# RX64M_POE_Pilot register map
File version: 1.0
RX64M_POE_Pilot peripheral registers generated from iodefine.h (pilot).
Registers are 16-bit, read-write, reset 0x0 unless marked. A register's access mark holds for its fields unless they carry their own. Offsets are from the block's base; lines under a group give offsets from that group; [hi:lo] are bit positions; {n}, {i} and the like mark numbered series; 'fields as' and 'values as' point back to an identical list; <NAME> marks a mode.

## Memory map
0x0008C4C0 POE3 size 0x2A

## POE3
Base 0x0008C4C0
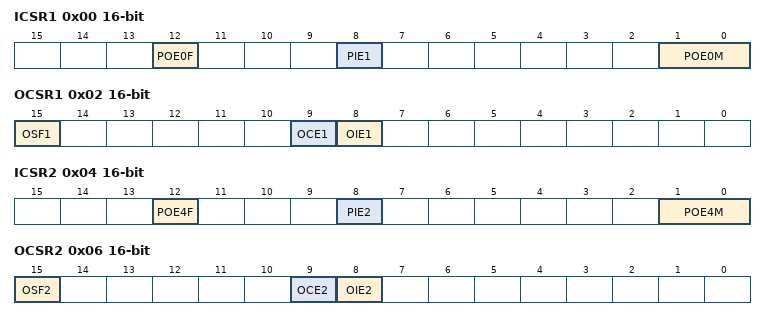
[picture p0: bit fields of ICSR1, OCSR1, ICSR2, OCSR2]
0x00 ICSR1
  [12] POE0F, [8] PIE1, [1:0] POE0M
0x02 OCSR1
  [15] OSF1, [9] OCE1, [8] OIE1
0x04 ICSR2
  [12] POE4F, [8] PIE2, [1:0] POE4M
0x06 OCSR2
  [15] OSF2, [9] OCE2, [8] OIE2
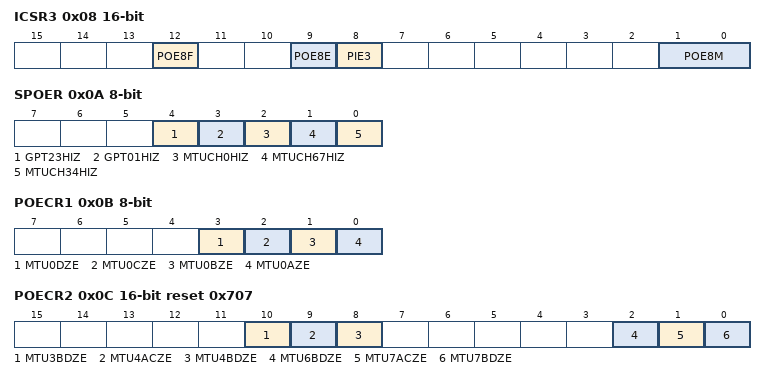
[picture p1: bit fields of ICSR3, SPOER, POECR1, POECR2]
0x08 ICSR3
  [12] POE8F, [9] POE8E, [8] PIE3, [1:0] POE8M
0x0A SPOER 8-bit
  [4] GPT23HIZ, [3] GPT01HIZ, [2] MTUCH0HIZ, [1] MTUCH67HIZ, [0] MTUCH34HIZ
0x0B POECR1 8-bit
  [3] MTU0DZE, [2] MTU0CZE, [1] MTU0BZE, [0] MTU0AZE
0x0C POECR2 reset 0x707
  [10] MTU3BDZE, [9] MTU4ACZE, [8] MTU4BDZE, [2] MTU6BDZE, [1] MTU7ACZE, [0] MTU7BDZE
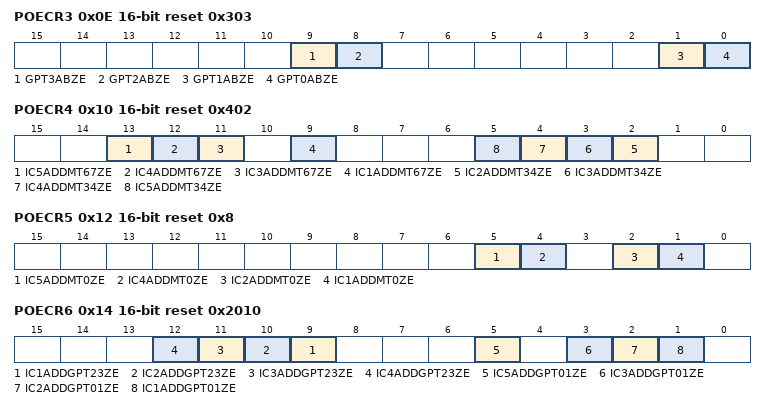
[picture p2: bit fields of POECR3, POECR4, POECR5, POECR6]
0x0E POECR3 reset 0x303
  [9] GPT3ABZE, [8] GPT2ABZE, [1] GPT1ABZE, [0] GPT0ABZE
0x10 POECR4 reset 0x402
  [13] IC5ADDMT67ZE, [12] IC4ADDMT67ZE, [11] IC3ADDMT67ZE, [9] IC1ADDMT67ZE, [n] IC{n}ADDMT34ZE (n=2..5)
0x12 POECR5 reset 0x8
  [5] IC5ADDMT0ZE, [4] IC4ADDMT0ZE, [2] IC2ADDMT0ZE, [1] IC1ADDMT0ZE
0x14 POECR6 reset 0x2010
  [n+8] IC{n}ADDGPT23ZE (n=1..4), [5] IC5ADDGPT01ZE, [3] IC3ADDGPT01ZE, [2] IC2ADDGPT01ZE, [1] IC1ADDGPT01ZE
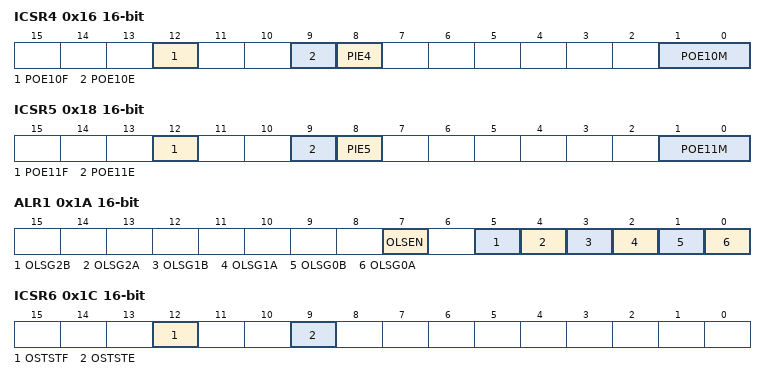
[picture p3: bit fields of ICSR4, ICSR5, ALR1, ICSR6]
0x16 ICSR4
  [12] POE10F, [9] POE10E, [8] PIE4, [1:0] POE10M
0x18 ICSR5
  [12] POE11F, [9] POE11E, [8] PIE5, [1:0] POE11M
0x1A ALR1
  [7] OLSEN, [5] OLSG2B, [4] OLSG2A, [3] OLSG1B, [2] OLSG1A, [1] OLSG0B, [0] OLSG0A
0x1C ICSR6
  [12] OSTSTF, [9] OSTSTE
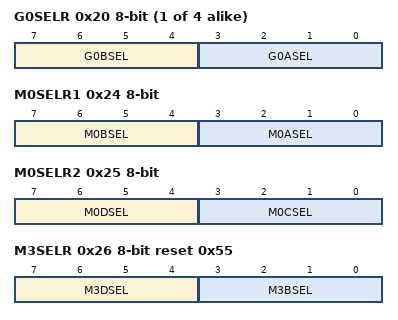
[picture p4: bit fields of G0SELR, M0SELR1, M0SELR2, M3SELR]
{0x20+i} G{i}SELR 8-bit (i=0..3)
  [7:4] G{i}BSEL, [3:0] G{i}ASEL
0x24 M0SELR1 8-bit
  [7:4] M0BSEL, [3:0] M0ASEL
0x25 M0SELR2 8-bit
  [7:4] M0DSEL, [3:0] M0CSEL
0x26 M3SELR 8-bit reset 0x55
  [7:4] M3DSEL, [3:0] M3BSEL
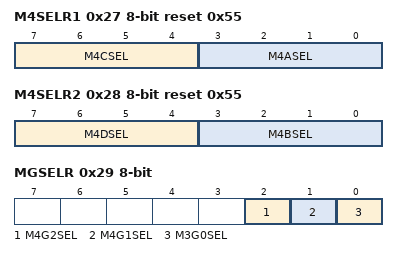
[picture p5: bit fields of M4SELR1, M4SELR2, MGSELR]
0x27 M4SELR1 8-bit reset 0x55
  [7:4] M4CSEL, [3:0] M4ASEL
0x28 M4SELR2 8-bit reset 0x55
  [7:4] M4DSEL, [3:0] M4BSEL
0x29 MGSELR 8-bit
  [2] M4G2SEL, [1] M4G1SEL, [0] M3G0SEL
